VERSION ""

NS_ :

BS_:

BU_: BMSLV MCU TCU

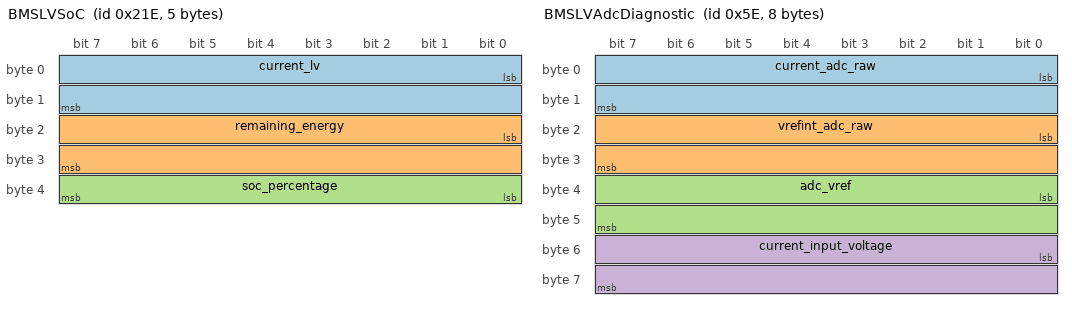
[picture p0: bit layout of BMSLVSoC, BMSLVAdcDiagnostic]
BO_ 542 BMSLVSoC: 5 BMSLV
 SG_ current_lv : 0|16@1- (0.01,0) [0|0] "A" MCU,TCU
 SG_ remaining_energy : 16|16@1+ (0.1,0) [0|648] "Wh" MCU,TCU
 SG_ soc_percentage : 32|8@1+ (1,0) [0|100] "%" MCU,TCU

BO_ 94 BMSLVAdcDiagnostic: 8 BMSLV
 SG_ current_adc_raw : 0|16@1+ (1,0) [0|4095] "count" MCU,TCU
 SG_ vrefint_adc_raw : 16|16@1+ (1,0) [0|4095] "count" MCU,TCU
 SG_ adc_vref : 32|16@1+ (1,0) [0|65535] "mV" MCU,TCU
 SG_ current_input_voltage : 48|16@1+ (1,0) [0|65535] "mV" MCU,TCU

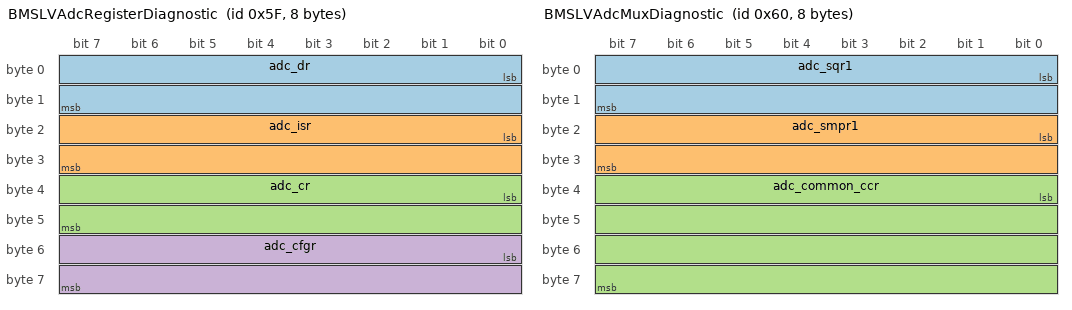
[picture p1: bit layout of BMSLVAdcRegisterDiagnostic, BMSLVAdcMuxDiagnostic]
BO_ 95 BMSLVAdcRegisterDiagnostic: 8 BMSLV
 SG_ adc_dr : 0|16@1+ (1,0) [0|65535] "" MCU,TCU
 SG_ adc_isr : 16|16@1+ (1,0) [0|65535] "" MCU,TCU
 SG_ adc_cr : 32|16@1+ (1,0) [0|65535] "" MCU,TCU
 SG_ adc_cfgr : 48|16@1+ (1,0) [0|65535] "" MCU,TCU

BO_ 96 BMSLVAdcMuxDiagnostic: 8 BMSLV
 SG_ adc_sqr1 : 0|16@1+ (1,0) [0|65535] "" MCU,TCU
 SG_ adc_smpr1 : 16|16@1+ (1,0) [0|65535] "" MCU,TCU
 SG_ adc_common_ccr : 32|32@1+ (1,0) [0|4294967295] "" MCU,TCU

BO_ 97 BMSLVAdcCalibrationDiagnostic: 8 BMSLV
 SG_ adc_difsel : 0|32@1+ (1,0) [0|4294967295] "" MCU,TCU
 SG_ adc_calfact : 32|32@1+ (1,0) [0|4294967295] "" MCU,TCU

BO_ 98 BMSLVAdcGpioDiagnostic: 8 BMSLV
 SG_ gpioa_moder : 0|32@1+ (1,0) [0|4294967295] "" MCU,TCU
 SG_ gpioa_pupdr : 32|32@1+ (1,0) [0|4294967295] "" MCU,TCU

BO_ 99 BMSLVAdcClockDiagnostic: 8 BMSLV
 SG_ adc_smpr2 : 0|32@1+ (1,0) [0|4294967295] "" MCU,TCU
 SG_ rcc_ccipr5 : 32|32@1+ (1,0) [0|4294967295] "" MCU,TCU

BO_ 101 BMSLVAdcOptionDiagnostic: 8 BMSLV
 SG_ adc_or : 0|32@1+ (1,0) [0|4294967295] "" MCU,TCU
 SG_ adc_cfgr2 : 32|32@1+ (1,0) [0|4294967295] "" MCU,TCU
